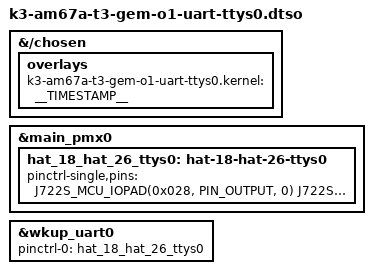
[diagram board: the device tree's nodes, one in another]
// SPDX-License-Identifier: GPL-2.0-only OR MIT
/*
 * DT Overlay to use GPIO24 (TX) and GPIO7 (RX) within the expansion header for WKUP_UART0 (ttyS0).
 *
 * Copyright (C) 2025 T3 Foundation - https://www.t3vakfi.org/
 */

/dts-v1/;
/plugin/;

#include <dt-bindings/gpio/gpio.h>
#include "k3-pinctrl.h"

/*
 * Helper to show loaded overlays under: /proc/device-tree/chosen/overlays/
*/
&{/chosen} {
	overlays {
		k3-am67a-t3-gem-o1-uart-ttys0.kernel = __TIMESTAMP__;
	};
};

&main_pmx0 {
    hat_18_hat_26_ttys0: hat-18-hat-26-ttys0 {
		pinctrl-single,pins = <
			J722S_MCU_IOPAD(0x028, PIN_OUTPUT, 0) /* (C8) WKUP_UART0_TXD */
			J722S_MCU_IOPAD(0x024, PIN_INPUT, 0) /* (B3) WKUP_UART0_RXD */
		>;
    };
};

&wkup_uart0 {
	pinctrl-names = "default";
	pinctrl-0 = <&hat_18_hat_26_ttys0>;
	status = "okay";
};
